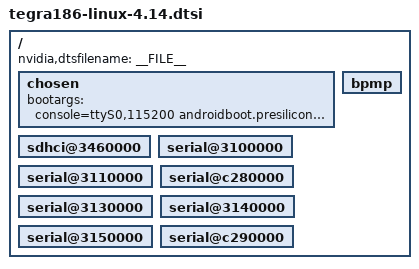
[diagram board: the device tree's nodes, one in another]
/*
 * tegra186-linux-4.14.dtsi
 *
 * Copyright (c) 2018, NVIDIA CORPORATION.  All rights reserved.
 *
 * This program is free software; you can redistribute it and/or modify
 * it under the terms of the GNU General Public License as published by
 * the Free Software Foundation; version 2 of the License.
 *
 * This program is distributed in the hope that it will be useful, but WITHOUT
 * ANY WARRANTY; without even the implied warranty of MERCHANTABILITY or
 * FITNESS FOR A PARTICULAR PURPOSE.  See the GNU General Public License for
 * more details.
 */

/ {
	nvidia,dtsfilename = __FILE__;

	/* Make SELinux permissive mode */
	chosen {
		 bootargs ="console=ttyS0,115200 androidboot.presilicon=true firmware_class.path=/etc/firmware androidboot.selinux=permissive";
	};

	/* Disable HS400 for emmc */
	sdhci@3460000 {
		/delete-property/ mmc-ddr-1_8v;
		/delete-property/ mmc-hs400-1_8v;
	};

	/* Disable smmu for sdhci, bpmp, uart */
	sdhci@3460000 {
		/delete-property/ iommus;
	};

	bpmp {
		/delete-property/ iommus;
	};

	serial@3100000 {
		/delete-property/ iommus;
	};

	serial@3110000 {
		/delete-property/ iommus;
	};

	serial@c280000 {
		/delete-property/ iommus;
	};

	serial@3130000 {
		/delete-property/ iommus;
	};

	serial@3140000 {
		/delete-property/ iommus;
	};

	serial@3150000 {
		/delete-property/ iommus;
	};

	serial@c290000 {
		/delete-property/ iommus;
	};
};
